# RL6955_IP_SVD register map
Vendor: Realtek
Registers are 32-bit, read-write, reset 0x0 unless marked. A register's access mark holds for its fields unless they carry their own. Offsets are from the block's base; [hi:lo] are bit positions; {n}, {i} and the like mark numbered series.

## WDMA
Base 0x40000000
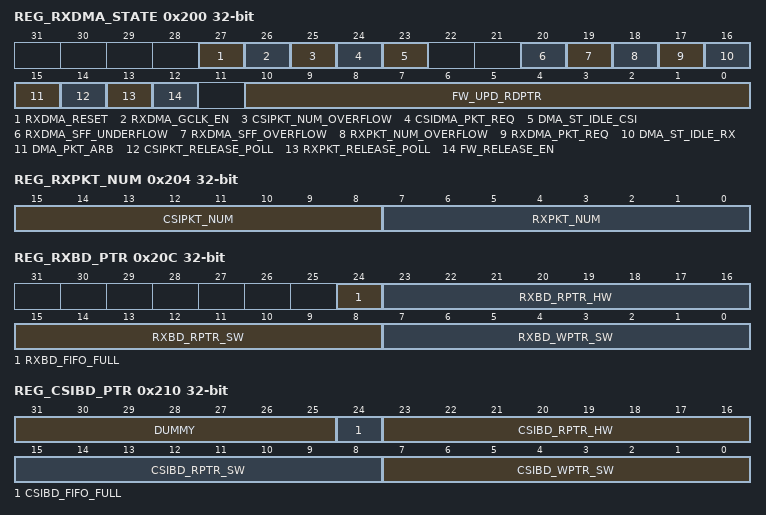
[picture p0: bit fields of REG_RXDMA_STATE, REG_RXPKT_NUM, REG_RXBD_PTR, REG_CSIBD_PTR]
0x200 REG_RXDMA_STATE access per field
  [27] RXDMA_RESET wo — when set to 1, enable rxdma ctl state set to IDLE
  [26] RXDMA_GCLK_EN rw — when set to 1, enable rxdma clock gating funtion
  [25] CSIPKT_NUM_OVERFLOW ro — csipkt number in CSIPKTBUFFER greater than 255
  [24] CSIDMA_PKT_REQ ro — csidma has request
  [23] DMA_ST_IDLE_CSI ro — csidma is idle
  [20] RXDMA_SFF_UNDERFLOW ro — rxdma syncfifo is underflow
  [19] RXDMA_SFF_OVERFLOW ro — rxdma syncfifo is overflow
  [18] RXPKT_NUM_OVERFLOW ro — rxpkt number in RXPKTBUFFER greater than 255
  [17] RXDMA_PKT_REQ ro — rxdma has request
  [16] DMA_ST_IDLE_RX ro — rxdma is idle
  [15] DMA_PKT_ARB rw
  [14] CSIPKT_RELEASE_POLL wo — One pulse. When this bit is set, RXDMA will decrease CSI PKT counter by one. Before this bit is polled, FW shall update RXFF_RD_PTR first.
  [13] RXPKT_RELEASE_POLL wo — One pulse. When this bit is set, RXDMA will decrease RX PKT counter by one. Before this bit is polled, FW shall update RXFF_RD_PTR first.
  [12] FW_RELEASE_EN rw — When this bit is set, RXDMA will stop after on-going RXDMA packet to host completed
  [10:0] FW_UPD_RDPTR rw — FW shall update this register before FW write RXPKT_RELEASE_POLL to 1. 8bytes unit
0x204 REG_RXPKT_NUM ro
  [15:8] CSIPKT_NUM — The number of packets in CSIPKTBUF.
  [7:0] RXPKT_NUM — The number of packets in RXPKTBUF.
0x208 REG_WDMA_DEBUG ro
  [31:0] WDMA_DBG — debug signal of WDMA_TOP
0x20C REG_RXBD_PTR ro
  [24] RXBD_FIFO_FULL — Available rxbd and used rxbd is equal to total rxbd number
  [23:16] RXBD_RPTR_HW — read pointer of HW of RXBD MEM
  [15:8] RXBD_RPTR_SW — read pointer of SW of RXBD MEM
  [7:0] RXBD_WPTR_SW — write pointer of SW of RXBD MEM
0x210 REG_CSIBD_PTR access per field
  [31:25] DUMMY rw
  [24] CSIBD_FIFO_FULL ro — Available csibd and used csibd is equal to total rxbd number
  [23:16] CSIBD_RPTR_HW ro — read pointer of HW of CSIBD MEM
  [15:8] CSIBD_RPTR_SW ro — read pointer of SW of CSIBD MEM
  [7:0] CSIBD_WPTR_SW ro — write pointer of SW of CSIBD MEM
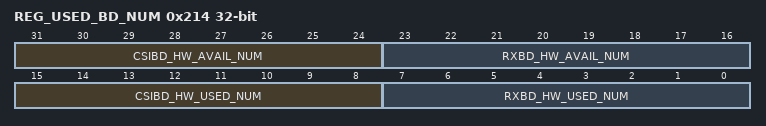
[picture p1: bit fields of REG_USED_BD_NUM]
0x214 REG_USED_BD_NUM ro
  [31:24] CSIBD_HW_AVAIL_NUM — available csibd number
  [23:16] RXBD_HW_AVAIL_NUM — available rxbd number
  [15:8] CSIBD_HW_USED_NUM — used csibd number
  [7:0] RXBD_HW_USED_NUM — used rxbd number

## AHB_LOCAL
Base 0x40000000
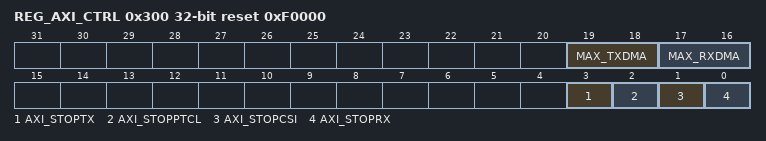
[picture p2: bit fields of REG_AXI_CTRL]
0x300 REG_AXI_CTRL reset 0xF0000
  [19:18] MAX_TXDMA — RXDMA Burst Size selection default 3. 0: 4bytes; 1: 16bytes; 2: 32bytes; 3: 64bytes
  [17:16] MAX_RXDMA — TXDMA Burst Size selection default 3. 0: 4bytes; 1: 16bytes; 2: 32bytes; 3: 64bytes.
  [3] AXI_STOPTX — TX packet DMA STOP
  [2] AXI_STOPPTCL — PTCL packet DMA STOP
  [1] AXI_STOPCSI — CSI packet DMA STOP
  [0] AXI_STOPRX — RX packet DMA STOP
0x304 Dummy

## SHA_KEY_REG
Base 0x400C4000
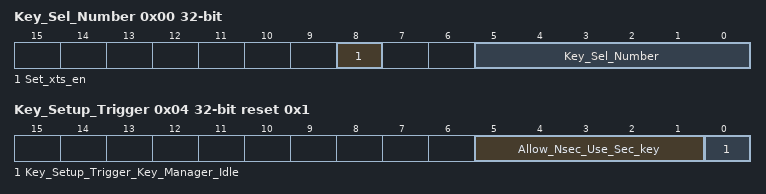
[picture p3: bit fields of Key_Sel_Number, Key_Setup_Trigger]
0x00 Key_Sel_Number — Key Selection Number Register
  [8] Set_xts_en — Only available when SUPPORT_XTS_MODE = 1. When this bit is set to 1, the trigger will write the selected key to xts_key2. Otherwise, the trigger will write the selected key to key/xts_key1.
  [5:0] Key_Sel_Number — The key number determines which key to use in the key setting. HW keys: 0~31, the number can be used is determined by the number of HW keys configured. Hardwired key: 32, if enabled Secure SW key: 33 Shared SW key: 34~ , the number can be used is determined by the number of SW keys configured.
0x04 Key_Setup_Trigger access per field reset 0x1 — Key Setup Process Trigger Register
  [5:1] Allow_Nsec_Use_Sec_key ro — When setting this field to 1, allow non-secure domain to trigger the secure key. Only secure domain can write this bit. The corresponding bits will be numbered from smallest to largest. For example, the number of the secure domain key is 0, 1, 33. Bits 0, 1, 2 control key0, key1, key33 respectively.
  [0] Key_Setup_Trigger_Key_Manager_Idle rw — Write 1 to trigger key setup process If the selected key is a hardware key, assert hw_key_req and wait for hw_key_ack. The key setup process will not start until hw_key_ack is received. The key managment unit uses the APB interface to pass the key into the engine according to the selected key. The read data represents whether the engine is idle or not. 0: Key setup process ongoing 1: Key setup is completed After triggering the key setup process, read this bit to confirm completion.
0x10 Secure_key0_7 — Secure key0 Register[255:224]
  [31:0] Secure_Key0_7 — Secure key0 register[32*7+31:31*7]
0x14 Secure_key0_6 — Secure key0 Register[223:192]
  [31:0] Secure_Key0_6 — Secure key0 register[32*6+31:31*6]
0x18 Secure_key0_5 — Secure key0 Register[191:160]
  [31:0] Secure_Key0_5 — Secure key0 register[32*5+31:31*5]
0x1C Secure_key0_4 — Secure key0 Register[159:128]
  [31:0] Secure_Key0_4 — Secure key0 register[32*4+31:31*4]
0x20 Secure_key0_3 — Secure key0 Register[127:96]
  [31:0] Secure_Key0_3 — Secure key0 register[32*3+31:31*3]
0x24 Secure_key0_2 — Secure key0 Register[95:64]
  [31:0] Secure_Key0_2 — Secure key0 register[32*2+31:31*2]
0x28 Secure_key0_1 — Secure key0 Register[63:32]
  [31:0] Secure_Key0_1 — Secure key0 register[32*1+31:31*1]
0x2C Secure_key0_0 — Secure key0 Register[31:0]
  [31:0] Secure_Key0_0 — Secure key0 register[32*0+31:31*0]
0x30 Shared_key0_7 — Shared key0 Register[255:224]
  [31:0] Shared_Key0_7 — Shared key0 register[32*7+31:32*7]
0x34 Shared_key0_6 — Shared key0 Register[223:192]
  [31:0] Shared_Key0_6 — Shared key0 register[32*6+31:32*6]
0x38 Shared_key0_5 — Shared key0 Register[191:160]
  [31:0] Shared_Key0_5 — Shared key0 register[32*5+31:32*5]
0x3C Shared_key0_4 — Shared key0 Register[159:128]
  [31:0] Shared_Key0_4 — Shared key0 register[32*4+31:32*4]
0x40 Shared_key0_3 — Shared key0 Register[127:96]
  [31:0] Shared_Key0_3 — Shared key0 register[32*3+31:32*3]
0x48 Shared_key0_2 — Shared key0 Register[95:64]
  [31:0] Shared_Key0_2 — Shared key0 register[32*2+31:32*2]
0x48 Shared_key0_1 — Shared key0 Register[63:32]
  [31:0] Shared_Key0_1 — Shared key0 register[32*1+31:32*1]
0x4C Shared_key0_0 — Shared key0 Register[31:0]
  [31:0] Shared_Key0_0 — Shared key0 register[32*0+31:32*0]

## UVC_REG
Base 0x41871000
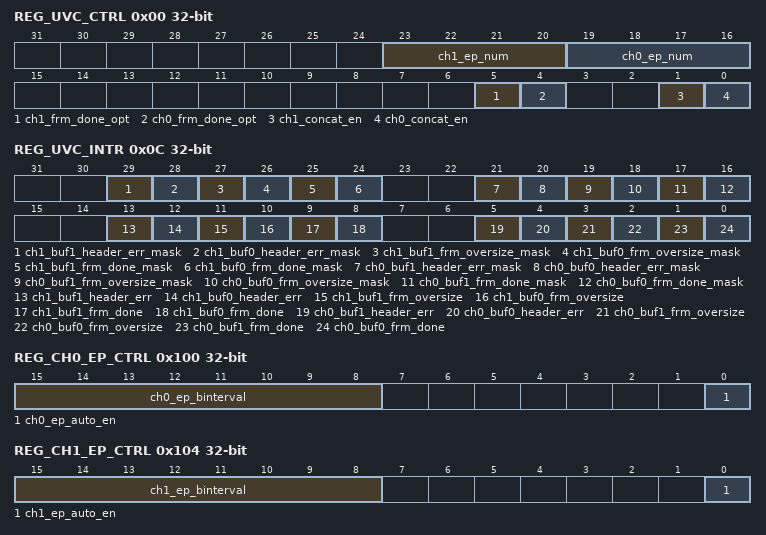
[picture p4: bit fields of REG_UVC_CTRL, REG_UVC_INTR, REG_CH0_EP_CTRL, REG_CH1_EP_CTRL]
0x00 REG_UVC_CTRL
  [23:20] ch1_ep_num
  [19:16] ch0_ep_num
  [5] ch1_frm_done_opt — 1: frame_done when xfercomp at EOF flag 0: frame_done when frame id changing
  [4] ch0_frm_done_opt — 1: frame_done when xfercomp at EOF flag 0: frame_done when frame id changing
  [1] ch1_concat_en
  [0] ch0_concat_en
0x04 REG_UVC_CHNL0_CTRL
  [31:0] ch0_dma_addr — For checking ahb xfer with header, this value should be the same as HCDMAi in otg_core
0x08 REG_UVC_CHNL1_CTRL
  [31:0] ch1_dma_addr — For checking ahb xfer with header, this value should be the same as HCDMAi in otg_core
0x0C REG_UVC_INTR access per field
  [29] ch1_buf1_header_err_mask rw, [28] ch1_buf0_header_err_mask rw, [27] ch1_buf1_frm_oversize_mask rw, [26] ch1_buf0_frm_oversize_mask rw, [25] ch1_buf1_frm_done_mask rw, [24] ch1_buf0_frm_done_mask rw, [21] ch0_buf1_header_err_mask rw, [20] ch0_buf0_header_err_mask rw, [19] ch0_buf1_frm_oversize_mask rw, [18] ch0_buf0_frm_oversize_mask rw, [17] ch0_buf1_frm_done_mask rw, [16] ch0_buf0_frm_done_mask rw, [13] ch1_buf1_header_err ro, [12] ch1_buf0_header_err ro, [11] ch1_buf1_frm_oversize ro, [10] ch1_buf0_frm_oversize ro, [9] ch1_buf1_frm_done ro, [8] ch1_buf0_frm_done ro, [5] ch0_buf1_header_err ro, [4] ch0_buf0_header_err ro, [3] ch0_buf1_frm_oversize ro, [2] ch0_buf0_frm_oversize ro, [1] ch0_buf1_frm_done ro, [0] ch0_buf0_frm_done ro
0x10 REG_CH0_BUF0_START_ADDR
  [31:0] ch0_buf0_start_addr
0x14 REG_CH0_BUF0_END_ADDR
  [31:0] ch0_buf0_end_addr
0x18 REG_CH0_BUF0_FRM_SIZE ro
  [23:0] ch0_buf0_frm_size
0x1C REG_CH0_BUF0_PTS ro
  [31:0] ch0_buf0_pts
0x20 REG_CH0_BUF0_SCR_FIRST ro
  [31:0] ch0_buf0_scr_first
0x24 REG_CH0_BUF0_SCR_LAST ro
  [31:0] ch0_buf0_scr_last
0x28 REG_CH0_BUF0_SOF_CNT ro
  [15:0] ch0_buf0_sof_cnt
0x30 REG_CH0_BUF1_START_ADDR
  [31:0] ch0_buf1_start_addr
0x34 REG_CH0_BUF1_END_ADDR
  [31:0] ch0_buf1_end_addr
0x38 REG_CH0_BUF1_FRM_SIZE ro
  [23:0] ch0_buf1_frm_size
0x3C REG_CH0_BUF1_PTS ro
  [31:0] ch0_buf1_pts
0x40 REG_CH0_BUF1_SCR_FIRST ro
  [31:0] ch0_buf1_scr_first
0x44 REG_CH0_BUF1_SCR_LAST ro
  [31:0] ch0_buf1_scr_last
0x48 REG_CH0_BUF1_SOF_CNT ro
  [15:0] ch0_buf1_sof_cnt
0x50 REG_CH1_BUF0_START_ADDR
  [31:0] ch1_buf0_start_addr
0x54 REG_CH1_BUF0_END_ADDR
  [31:0] ch1_buf0_end_addr
0x58 REG_CH1_BUF0_FRM_SIZE ro
  [23:0] ch1_buf0_frm_size
0x5C REG_CH1_BUF0_PTS ro
  [31:0] ch1_buf0_pts
0x60 REG_CH1_BUF0_SCR_FIRST ro
  [31:0] ch1_buf0_scr_first
0x64 REG_CH1_BUF0_SCR_LAST ro
  [31:0] ch1_buf0_scr_last
0x68 REG_CH1_BUF0_SOF_CNT ro
  [15:0] ch1_buf0_sof_cnt
0x70 REG_CH1_BUF1_START_ADDR
  [31:0] ch1_buf1_start_addr
0x74 REG_CH1_BUF1_END_ADDR
  [31:0] ch1_buf1_end_addr
0x78 REG_CH1_BUF1_FRM_SIZE ro
  [23:0] ch1_buf1_frm_size
0x7C REG_CH1_BUF1_PTS ro
  [31:0] ch1_buf1_pts
0x80 REG_CH1_BUF1_SCR_FIRST ro
  [31:0] ch1_buf1_scr_first
0x84 REG_CH1_BUF1_SCR_LAST ro
  [31:0] ch1_buf1_scr_last
0x88 REG_CH1_BUF1_SOF_CNT ro
  [15:0] ch1_buf1_sof_cnt
0x100 REG_CH0_EP_CTRL
  [15:8] ch0_ep_binterval, [0] ch0_ep_auto_en
0x104 REG_CH1_EP_CTRL
  [15:8] ch1_ep_binterval, [0] ch1_ep_auto_en
0x10C REG_HST_FRREM_CTRL reset 0x10
  [15:0] hst_frremain_thresh — threshold for checking hst_frrem if hst_frrem(otg_core) > threshold, enable iso endpoint in this frame else, enable iso endpoint in next frame
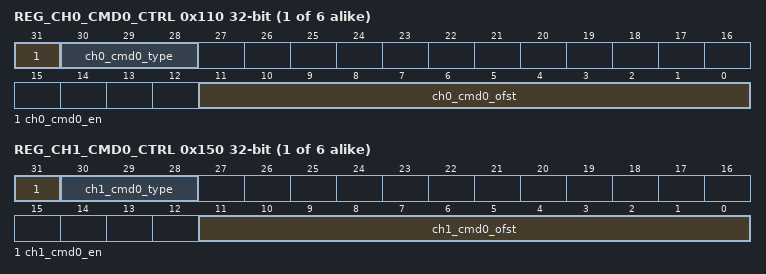
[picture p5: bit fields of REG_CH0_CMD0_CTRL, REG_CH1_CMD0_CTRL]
{0x110+8i} REG_CH0_CMD{i}_CTRL (i=0..5)
  [31] ch0_cmd{i}_en, [30:28] ch0_cmd{i}_type, [11:0] ch0_cmd{i}_ofst
{0x114+8i} REG_CH0_CMD{i}_DATA (i=0..5)
  [31:0] ch0_cmd{i}_data
{0x150+8i} REG_CH1_CMD{i}_CTRL (i=0..5)
  [31] ch1_cmd{i}_en, [30:28] ch1_cmd{i}_type, [11:0] ch1_cmd{i}_ofst
{0x154+8i} REG_CH1_CMD{i}_DATA (i=0..5)
  [31:0] ch1_cmd{i}_data
